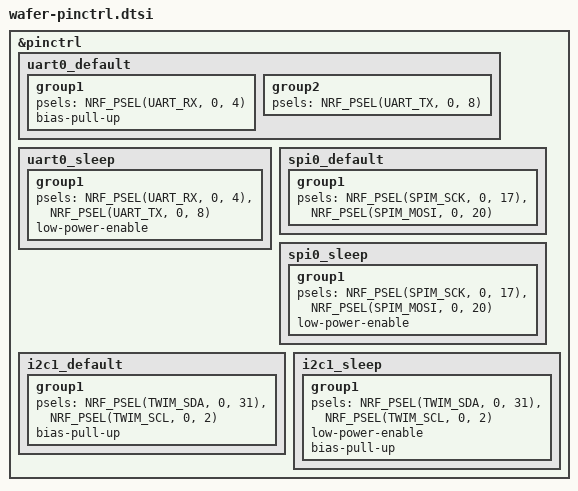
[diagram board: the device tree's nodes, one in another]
/*
 * Copyright (c) 2022 The ZMK Contributors
 * SPDX-License-Identifier: MIT
 */

&pinctrl {
    /* Debug UART on P0.04 (RX) / P0.08 (TX) */
    uart0_default: uart0_default {
        group1 {
            psels = <NRF_PSEL(UART_RX, 0, 4)>;
            bias-pull-up;
        };
        group2 {
            psels = <NRF_PSEL(UART_TX, 0, 8)>;
        };
    };

    uart0_sleep: uart0_sleep {
        group1 {
            psels = <NRF_PSEL(UART_RX, 0, 4)>,
                    <NRF_PSEL(UART_TX, 0, 8)>;
            low-power-enable;
        };
    };

    /* nice!view / Sharp LS0xx SPI:
     * SCK  = P0.17
     * MOSI = P0.20
     * (3-wire, без MISO)
     */
    spi0_default: spi0_default {
        group1 {
            psels = <NRF_PSEL(SPIM_SCK, 0, 17)>,
                    <NRF_PSEL(SPIM_MOSI, 0, 20)>;
        };
    };

    spi0_sleep: spi0_sleep {
        group1 {
            psels = <NRF_PSEL(SPIM_SCK, 0, 17)>,
                    <NRF_PSEL(SPIM_MOSI, 0, 20)>;
            low-power-enable;
        };
    };

    /* I2C1: nPM1300
     * BAT_I2C_SDA = P0.31
     * BAT_I2C_SCL = P0.02
     */
    i2c1_default: i2c1_default {
        group1 {
            psels = <NRF_PSEL(TWIM_SDA, 0, 31)>,
                    <NRF_PSEL(TWIM_SCL, 0, 2)>;
            bias-pull-up;
        };
    };

    i2c1_sleep: i2c1_sleep {
        group1 {
            psels = <NRF_PSEL(TWIM_SDA, 0, 31)>,
                    <NRF_PSEL(TWIM_SCL, 0, 2)>;
            low-power-enable;
            bias-pull-up;
        };
    };
};
